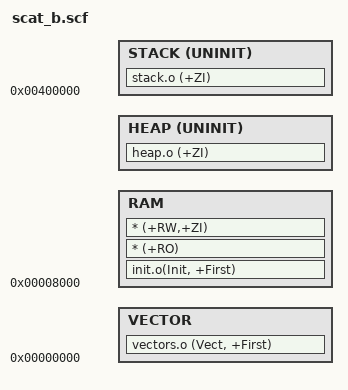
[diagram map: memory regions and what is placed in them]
;/******************************************************************************
; *
; * Copyright (c) 2003 Windond Electronics Corp.
; * All rights reserved.
; *
; * $Workfile: $
; *
; * $Author: $
; ******************************************************************************/
;/*
; * $History: $
; */
; RAM_LOAD region specifies the RO base 0x8000
; RAM region specifies the init.o first, RO, RW, ZI
; HEAP region specifies the heap base
; STACK region specifies the stack base
; VECTOR region specifies the vector table

;CAUTION: Don't modify this file. It may be used in other place at the same time.

RAM_LOAD 0x8000	
{
    RAM +0
    {
    	init.o(Init, +First)
        * (+RO)
        * (+RW,+ZI)
    }

    HEAP +0 UNINIT
    {
        heap.o (+ZI)
    }

	STACK 0x400000 UNINIT
	{
		stack.o (+ZI)
	}

    VECTOR 0x0
    {
        vectors.o (Vect, +First)
    }

}

